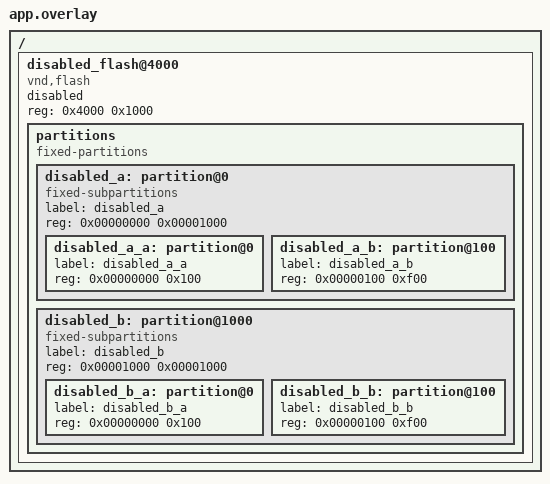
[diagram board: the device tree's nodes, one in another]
/*
 * Copyright (c) 2022, Commonwealth Scientific and Industrial Research
 * Organisation (CSIRO) ABN 41 687 119 230.
 *
 * SPDX-License-Identifier: Apache-2.0
 *
 * Test compilation with subpartitions and disabled flash nodes.
 */

/ {
	disabled_flash@4000 {
		compatible = "vnd,flash";
		reg = <0x4000 0x1000>;
		ranges = <0x0 0x4000 0x1000>;
		status = "disabled";
		#address-cells = <1>;
		#size-cells = <1>;

		partitions {
			compatible = "fixed-partitions";
			ranges;
			#address-cells = <1>;
			#size-cells = <1>;

			disabled_a: partition@0 {
				compatible = "fixed-subpartitions";
				label = "disabled_a";
				reg = <0x00000000 0x00001000>;
				ranges = <0x0 0x0 0x1000>;
				#address-cells = <1>;
				#size-cells = <1>;

				disabled_a_a: partition@0 {
					label = "disabled_a_a";
					reg = <0x00000000 0x100>;
				};

				disabled_a_b: partition@100 {
					label = "disabled_a_b";
					reg = <0x00000100 0xf00>;
				};
			};

			disabled_b: partition@1000 {
				compatible = "fixed-subpartitions";
				label = "disabled_b";
				reg = <0x00001000 0x00001000>;
				ranges = <0x0 0x1000 0x1000>;
				#address-cells = <1>;
				#size-cells = <1>;

				disabled_b_a: partition@0 {
					label = "disabled_b_a";
					reg = <0x00000000 0x100>;
				};

				disabled_b_b: partition@100 {
					label = "disabled_b_b";
					reg = <0x00000100 0xf00>;
				};
			};
		};
	};
};
